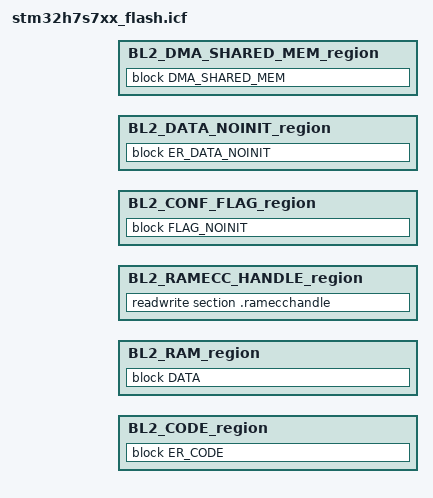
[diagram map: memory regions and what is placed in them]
#include "region_defs.h"

define memory mem with size = 4G;

define region BL2_CODE_region           = mem:[from BL2_CODE_START size BL2_CODE_SIZE];

define region BL2_RAM_region            = mem:[from BL2_DATA_START size BL2_DATA_SIZE];
define region BL2_RAMECC_HANDLE_region  = mem:[from BL2_RAMECC_HANDLE_START size BL2_RAMECC_HANDLE_SIZE];
define region BL2_CONF_FLAG_region      = mem:[from BL2_CONF_FLAG_START size BL2_CONF_FLAG_SIZE];
define region BL2_DATA_NOINIT_region    = mem:[from BL2_DATA_NOINIT_START size BL2_DATA_NOINIT_SIZE];
define region BL2_DMA_SHARED_MEM_region = mem:[from BL2_DMA_SHARED_MEM_START size BL2_DMA_SHARED_MEM_SIZE];

initialize by copy  with packing = none {  readwrite };
do not initialize  { section .noinit };
do not initialize  { section .flagnoinit };
define block ER_CODE  with fixed order, alignment = 8 {
       readonly,
       readonly section .BL2_Error_Code,
       };

place at address (BL2_BOOT_VTOR_ADDR) { readonly section .intvec };
place in BL2_CODE_region {block ER_CODE };

define block ER_DATA_NOINIT   with  alignment = 32 { section .noinit};
define block ER_DATA        with  alignment = 32 { readwrite};
define block FLAG_NOINIT { section .flagnoinit};
define block DMA_SHARED_MEM { section .dma_shared_mem };

define block ARM_LIB_STACK with alignment = 32, size = BL2_MSP_STACK_SIZE { };
define block HEAP   with alignment = 8, size = BL2_HEAP_SIZE { };

define block DATA with fixed order { block ER_DATA, block ARM_LIB_STACK, block HEAP };
place in BL2_RAM_region            { block DATA };
place in BL2_RAMECC_HANDLE_region  { readwrite section .ramecchandle };
keep { section .ramecchandle };
place in BL2_CONF_FLAG_region      { block FLAG_NOINIT };
place in BL2_DATA_NOINIT_region    { block ER_DATA_NOINIT };
place in BL2_DMA_SHARED_MEM_region { block DMA_SHARED_MEM };
